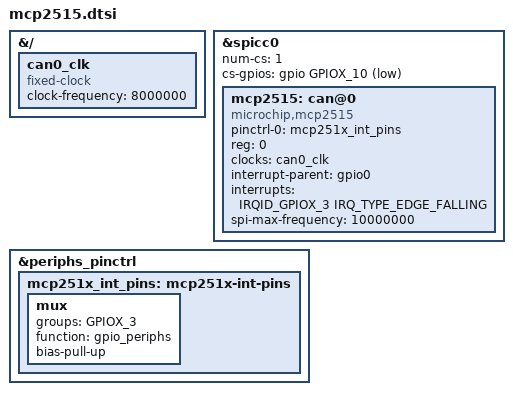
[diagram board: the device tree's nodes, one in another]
/dts-v1/;
/plugin/;

#include <dt-bindings/gpio/gpio.h>
#include <dt-bindings/gpio/meson-g12a-gpio.h>
#include <dt-bindings/interrupt-controller/irq.h>
#include <dt-bindings/interrupt-controller/amlogic,meson-g12a-gpio-intc.h>

&{/} {
	can0_clk: can0_clk {
		compatible = "fixed-clock";
		#clock-cells = <0>;
		clock-frequency = <8000000>;
	};
};

&spicc0 {
	num-cs = <1>;
	cs-gpios = <&gpio GPIOX_10 GPIO_ACTIVE_LOW>;
	status = "okay";
	#address-cells = <1>;
	#size-cells = <0>;

	mcp2515: can@0 {
		compatible = "microchip,mcp2515";
		pinctrl-names = "default";
		pinctrl-0 = <&mcp251x_int_pins>;
		reg = <0>;
		clocks = <&can0_clk>;
		interrupt-parent = <&gpio0>;
		interrupts = <IRQID_GPIOX_3 IRQ_TYPE_EDGE_FALLING>;
		spi-max-frequency = <10000000>;
		status = "okay";
	};
};

&periphs_pinctrl {
	mcp251x_int_pins: mcp251x-int-pins {
		mux {
			groups = "GPIOX_3";
			function = "gpio_periphs";
			bias-pull-up;
		};
	};
};
